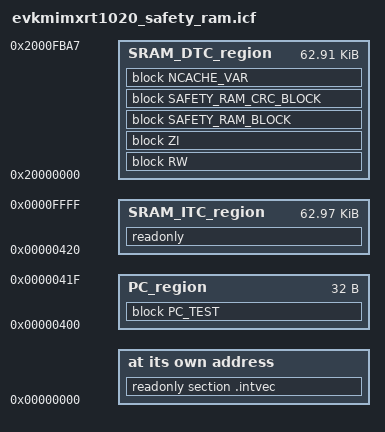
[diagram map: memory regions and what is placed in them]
/*
** ###################################################################
**     Processors:          MIMXRT1021CAF4A
**                          MIMXRT1021CAG4A
**                          MIMXRT1021DAF5A
**                          MIMXRT1021DAG5A
**
**     Compiler:            IAR ANSI C/C++ Compiler for ARM
**     Reference manual:    IMXRT1020RM.pdf
**
**     Abstract:
**         Linker file for the IAR ANSI C/C++ Compiler for ARM
**
**     Copyright 2019 NXP.
**     All rights reserved.
**
**     SPDX-License-Identifier: BSD-3-Clause
**
**     http:                 www.nxp.com
**     mail:                 support@nxp.com
**
** ###################################################################
*/

/**********************************************************************************/
/****************************        MEMORY MAP        ****************************/
/**********************************************************************************/

/********************        FLASH        ********************/
//     __________________
//    |                  | --> 0x60000000 - ROM_start
//    |//// NOT USED ////|
//    |__________________| --> 0x63FFFFFF - ROM_end
//
//
/********************        SRAM        ********************/
//     __________________
//    |                  | --> 0x00000000 - RAM_interrupts_start
//    |       IVT        |
//    |__________________| --> 0x000003FF - RAM_interrupts_end 
//    |                  | --> 0x00000400 - SRAM_ITC_start
//    |     readonly     |
//    |__________________| --> 0x0001FFFF - SRAM_ITC_end 
//    |                  |
//    |//// RESERVED ////|
//    |__________________|
//    |                  | --> 0x20000000 - SRAM_DTC_start
//    |     RW (.data)   | --> copying in startup_iar.c
//    |     ZI (.bss)    | --> copying in startup_iar.c
//    | SAFETY_RAM_BLOCK | 
//    |__________________| --> SRAM_DTC_end_edited
//    |                  | --> m_stack_test_p_1
//    |                  |
//    |__________________| --> m_stack_test_p_2
//    |                  |
//    |                  |
//    |      STACK       |
//    |                  |
//    |__________________| --> __BOOT_STACK_ADDRESS
//    |                  | --> m_stack_test_p_3
//    |                  |
//    |__________________| --> m_stack_test_p_4
//    |__________________| --> m_safety_error_code
//    |__________________| --> m_pc_test_flag
//    |                  | --> m_wd_test_backup
//    |__________________|
//    |                  |
//    |                  | --> m_ram_test_backup
//    |__________________|
//    |__________________| --> 0x2001FFFF - SRAM_DTC_end
//    |                  |
//    |//// RESERVED ////|
//    |__________________|
//    |                  | --> 0x20200000 - SRAM_OC_start
//    |//// NOT USED ////|
//    |__________________| --> 0x2023FFFF - SRAM_OC_end
//
//
/********************        SDRAM        ********************/
//     __________________
//    |                  | --> 0x80000000 - SDRAM_start
//    |//// NOT USED ////|
//    |__________________| --> 0x81FFFFFF - SDRAM_end
//
//

/******************************************************************************/
/******************     USER CONFIGURATION PART     ***************************/
/******************************************************************************/
define exported symbol stack_test_block_size = 0x10;
define exported symbol ram_test_backup_size  = 0x20;
define symbol __vector_table_size__          = 0x400;
define symbol __size_cstack__                = 0x0400;

define symbol RAM_interrupts_start = 0x00000000; /* IVT in RAM */
define symbol RAM_interrupts_end   = RAM_interrupts_start + __vector_table_size__ - 1;

define symbol __PC_test_start__    = RAM_interrupts_end + 1;       /* PC object address */
define symbol __PC_test_end__      = __PC_test_start__ + 0x20 - 1; /* PC object reserved size: 0x20 */ 

define symbol SRAM_ITC_start       = __PC_test_end__ + 1; /* Part of 512KB on-chip RAM (Instruction-Tightly-Coupled) */
define symbol SRAM_ITC_end         = 0x0000FFFF;

define symbol SRAM_DTC_start       = 0x20000000; /* Part of on-chip RAM (Data-Tightly-Coupled) */
define symbol SRAM_DTC_end         = 0x2000FFFF;

define exported symbol __VECTOR_TABLE = RAM_interrupts_start;

/***** NOT USED IN THIS EXAMPLE *****/
define symbol SRAM_OC_start = 0x20200000; /* Part of on-chip RAM */
define symbol SRAM_OC_end   = 0x2021FFFF;

define symbol ROM_start     = 0x60000000; /* ROM memory (external ROM) */
define symbol ROM_end       = 0x607FFFFF;

define symbol SDRAM_start   = 0x80000000; /* SDRAM memory (external RAM) */
define symbol SDRAM_end     = 0x81FFFFFF;
/***** NOT USED IN THIS EXAMPLE *****/

/******************************************************************************/
/******************     SYMBOLS     *******************************************/
/******************************************************************************/   
define exported symbol m_ram_test_backup    = SRAM_DTC_end - ram_test_backup_size + 0x1;
define exported symbol m_wd_test_backup     = m_ram_test_backup - 0x10;
define exported symbol m_pc_test_flag       = m_wd_test_backup - 0x4;
define exported symbol m_safety_error_code  = m_pc_test_flag - 0x4;
define exported symbol m_stack_test_p_4     = m_safety_error_code - 0x4;
define exported symbol m_stack_test_p_3     = m_stack_test_p_4 - stack_test_block_size +0x4;
define exported symbol __BOOT_STACK_ADDRESS = m_stack_test_p_3 - 0x4;
define exported symbol m_stack_test_p_2     = __BOOT_STACK_ADDRESS - __size_cstack__;
define exported symbol m_stack_test_p_1     = m_stack_test_p_2 - stack_test_block_size + 0x4;
define symbol SRAM_DTC_end_edited           = m_stack_test_p_1 - 0x1;

/******************************************************************************/
/******************     REGIONS     *******************************************/
/******************************************************************************/
define memory mem with size   = 4G;
define region SRAM_ITC_region = mem:[from SRAM_ITC_start to SRAM_ITC_end];
define region SRAM_DTC_region = mem:[from SRAM_DTC_start to SRAM_DTC_end_edited];
define region PC_region       = mem:[from __PC_test_start__ to __PC_test_end__];

/******************************************************************************/
/******************     SECTIONS & BLOCKS    **********************************/
/******************************************************************************/
initialize manually           { readwrite };
initialize manually           { section .data };
initialize manually           { section .bss };
initialize manually           { section .textrw };
initialize manually           { section .safety_ram };
initialize manually           { section .safety_ram_crc };
do not initialize             { section .noinit };

define block RW               { readwrite };
define block ZI               { zi };
define block PC_TEST          { section .text object iec60730b_cm4_cm7_pc_object.o };
define block NCACHE_VAR       { section NonCacheable, section NonCacheable.init };
define block SAFETY_RAM_BLOCK { section .safety_ram };
define block SAFETY_RAM_CRC_BLOCK { section .safety_ram_crc };

/*****************************************************/
/******************     PLACING     ******************/
/*****************************************************/
place at address mem:RAM_interrupts_start { readonly section .intvec };

place in SRAM_ITC_region   { readonly };
place in PC_region         { block PC_TEST};
place in SRAM_DTC_region   { block RW };
place in SRAM_DTC_region   { block ZI };
place in SRAM_DTC_region   { block SAFETY_RAM_BLOCK };
place in SRAM_DTC_region   { block SAFETY_RAM_CRC_BLOCK };
place in SRAM_DTC_region   { block NCACHE_VAR };
